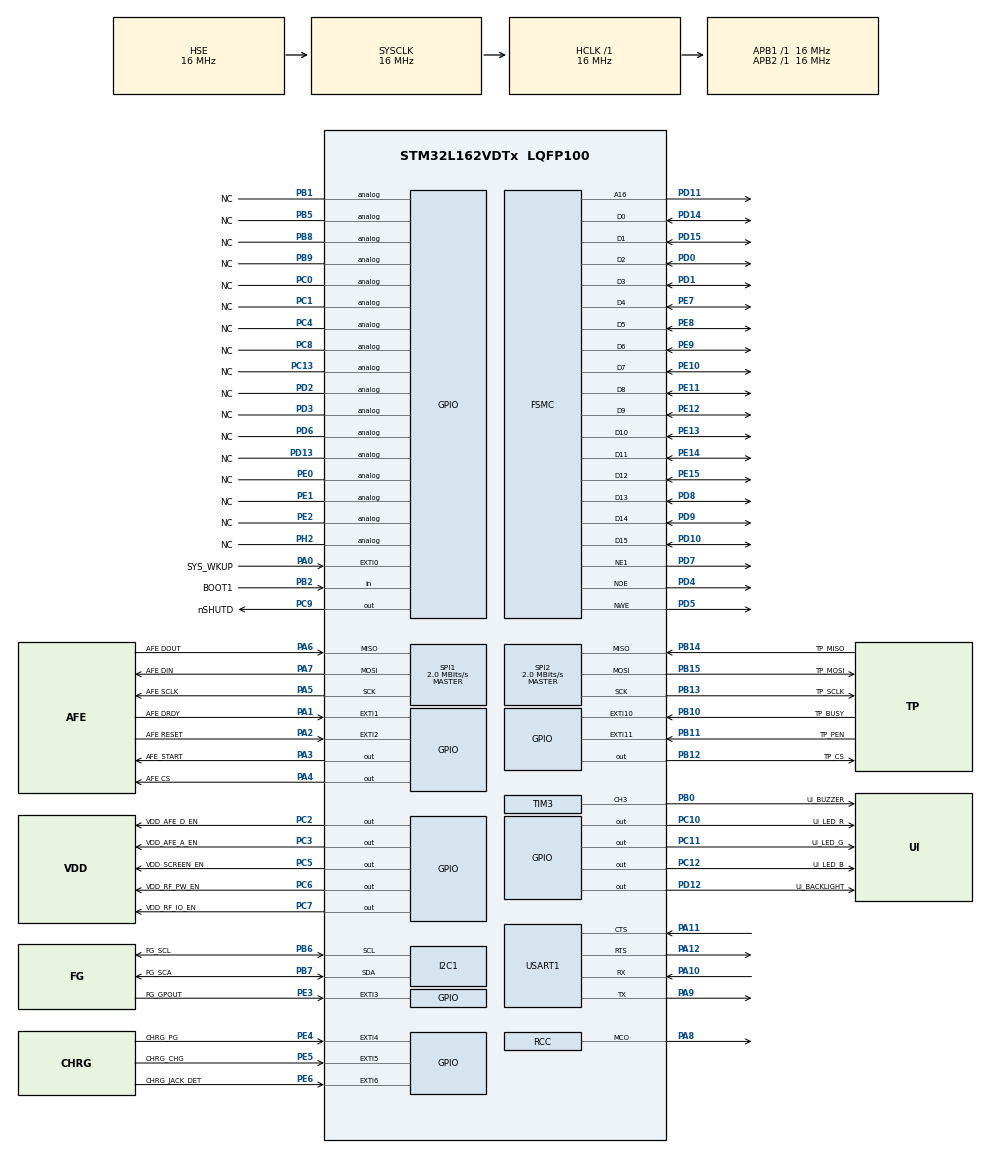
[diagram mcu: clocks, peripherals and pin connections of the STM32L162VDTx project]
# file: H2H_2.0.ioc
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Mcu.Family=STM32L1
Mcu.Name=STM32L162VDTx
Mcu.Package=LQFP100
NVIC.EXTI0_IRQn=true\:2\:0\:true\:false\:true
NVIC.EXTI15_10_IRQn=true\:6\:0\:true\:false\:true
NVIC.EXTI1_IRQn=true\:3\:0\:true\:false\:true
NVIC.EXTI3_IRQn=true\:4\:0\:true\:false\:true
NVIC.PriorityGroup=NVIC_PRIORITYGROUP_4
NVIC.TIM6_IRQn=true\:1\:0\:true\:false\:true
PA0-WKUP1.GPIO_Label=SYS_WKUP
PA0-WKUP1.Signal=GPXTI0
PA1.GPIO_Label=AFE DRDY
PA1.Signal=GPXTI1
PA10.Mode=Asynchronous
PA10.Signal=USART1_RX
PA11.Mode=CTS_RTS
PA11.Signal=USART1_CTS
PA12.Mode=CTS_RTS
PA12.Signal=USART1_RTS
PA13.Mode=JTAG(5-pin)
PA13.Signal=SYS_JTMS-SWDIO
PA14.Mode=JTAG(5-pin)
PA14.Signal=SYS_JTCK-SWCLK
PA15.Mode=JTAG(5-pin)
PA15.Signal=SYS_JTDI
PA2.GPIO_Label=AFE RESET
PA2.Signal=GPXTI2
PA3.GPIO_Label=AFE_START
PA3.Signal=GPIO_Output
PA4.GPIO_Label=AFE CS
PA4.Signal=GPIO_Output
PA5.GPIO_Label=AFE SCLK
PA5.Mode=Full_Duplex_Master
PA5.Signal=SPI1_SCK
PA6.GPIO_Label=AFE DOUT
PA6.Mode=Full_Duplex_Master
PA6.Signal=SPI1_MISO
PA7.GPIO_Label=AFE DIN
PA7.Mode=Full_Duplex_Master
PA7.Signal=SPI1_MOSI
PA8.Mode=Clock-out
PA8.Signal=RCC_MCO
PA9.Mode=Asynchronous
PA9.Signal=USART1_TX
PB0.GPIO_Label=UI_BUZZER
PB0.Signal=S_TIM3_CH3
PB1.GPIO_Label=NC
PB1.Signal=GPIO_Analog
PB10.GPIO_Label=TP_BUSY
PB10.Signal=GPXTI10
PB11.GPIO_Label=TP_PEN
PB11.GPIO_ModeDefaultEXTI=GPIO_MODE_IT_FALLING
PB11.Signal=GPXTI11
PB12.GPIO_Label=TP_CS
PB12.Signal=GPIO_Output
PB13.GPIO_Label=TP_SCLK
PB13.Mode=Full_Duplex_Master
PB13.Signal=SPI2_SCK
PB14.GPIO_Label=TP_MISO
PB14.Mode=Full_Duplex_Master
PB14.Signal=SPI2_MISO
PB15.GPIO_Label=TP_MOSI
PB15.Mode=Full_Duplex_Master
PB15.Signal=SPI2_MOSI
PB2.GPIO_Label=BOOT1
PB2.Signal=GPIO_Input
PB3.Mode=JTAG(5-pin)
PB3.Signal=SYS_JTDO-TRACESWO
PB4.Mode=JTAG(5-pin)
PB4.Signal=SYS_JTRST
PB5.GPIO_Label=NC
PB5.Signal=GPIO_Analog
PB6.GPIO_Label=FG_SCL
PB6.Mode=I2C
PB6.Signal=I2C1_SCL
PB7.GPIO_Label=FG_SCA
PB7.Mode=I2C
PB7.Signal=I2C1_SDA
PB8.GPIO_Label=NC
PB8.Signal=GPIO_Analog
PB9.GPIO_Label=NC
PB9.Signal=GPIO_Analog
PC0.GPIO_Label=NC
PC0.Signal=GPIO_Analog
PC1.GPIO_Label=NC
PC1.Signal=GPIO_Analog
PC10.GPIO_Label=UI_LED_R
PC10.GPIO_PuPd=GPIO_PULLDOWN
PC10.Signal=GPIO_Output
PC11.GPIO_Label=UI_LED_G
PC11.GPIO_PuPd=GPIO_PULLDOWN
PC11.Signal=GPIO_Output
PC12.GPIO_Label=UI_LED_B
PC12.GPIO_PuPd=GPIO_PULLDOWN
PC12.Signal=GPIO_Output
PC13-WKUP2.GPIO_Label=NC
PC13-WKUP2.Signal=GPIO_Analog
PC14-OSC32_IN.GPIO_Label=X2_P
PC14-OSC32_IN.Mode=LSE-External-Oscillator
PC14-OSC32_IN.Signal=RCC_OSC32_IN
PC15-OSC32_OUT.GPIO_Label=X2_N
PC15-OSC32_OUT.Mode=LSE-External-Oscillator
PC15-OSC32_OUT.Signal=RCC_OSC32_OUT
PC2.GPIO_Label=VDD_AFE_D_EN
PC2.PinState=GPIO_PIN_SET
PC2.Signal=GPIO_Output
PC3.GPIO_Label=VDD_AFE_A_EN
PC3.PinState=GPIO_PIN_SET
PC3.Signal=GPIO_Output
PC4.GPIO_Label=NC
PC4.Signal=GPIO_Analog
PC5.GPIO_Label=VDD_SCREEN_EN
PC5.PinState=GPIO_PIN_SET
PC5.Signal=GPIO_Output
PC6.GPIO_Label=VDD_RF_PW_EN
PC6.PinState=GPIO_PIN_SET
PC6.Signal=GPIO_Output
PC7.GPIO_Label=VDD_RF_IO_EN
PC7.PinState=GPIO_PIN_SET
PC7.Signal=GPIO_Output
PC8.GPIO_Label=NC
PC8.Signal=GPIO_Analog
PC9.GPIO_Label=nSHUTD
PC9.Signal=GPIO_Output
PD0.Mode=16b-d1
PD0.Signal=FSMC_D2
PD1.Mode=16b-d1
PD1.Signal=FSMC_D3
PD10.Mode=16b-d1
PD10.Signal=FSMC_D15
PD11.Mode=A16_1
PD11.Signal=FSMC_A16
PD12.GPIO_Label=UI_BACKLIGHT
PD12.PinState=GPIO_PIN_SET
PD12.Signal=GPIO_Output
PD13.GPIO_Label=NC
PD13.Signal=GPIO_Analog
PD14.Mode=16b-d1
PD14.Signal=FSMC_D0
PD15.Mode=16b-d1
PD15.Signal=FSMC_D1
PD2.GPIO_Label=NC
PD2.Signal=GPIO_Analog
PD3.GPIO_Label=NC
PD3.Signal=GPIO_Analog
PD4.Mode=Lcd1
PD4.Signal=FSMC_NOE
PD5.Mode=Lcd1
PD5.Signal=FSMC_NWE
PD6.GPIO_Label=NC
PD6.Signal=GPIO_Analog
PD7.Mode=NorPsramChipSelect1_1
PD7.Signal=FSMC_NE1
PD8.Mode=16b-d1
PD8.Signal=FSMC_D13
PD9.Mode=16b-d1
PD9.Signal=FSMC_D14
PE0.GPIO_Label=NC
PE0.Signal=GPIO_Analog
PE1.GPIO_Label=NC
PE1.Signal=GPIO_Analog
PE10.Mode=16b-d1
PE10.Signal=FSMC_D7
PE11.Mode=16b-d1
PE11.Signal=FSMC_D8
PE12.Mode=16b-d1
PE12.Signal=FSMC_D9
PE13.Mode=16b-d1
PE13.Signal=FSMC_D10
PE14.Mode=16b-d1
PE14.Signal=FSMC_D11
PE15.Mode=16b-d1
PE15.Signal=FSMC_D12
PE2.GPIO_Label=NC
PE2.Signal=GPIO_Analog
PE3.GPIO_Label=FG_GPOUT
PE3.GPIO_ModeDefaultEXTI=GPIO_MODE_IT_FALLING
PE3.Signal=GPXTI3
PE4.GPIO_Label=CHRG_PG
PE4.Signal=GPXTI4
PE5.GPIO_Label=CHRG_CHG
PE5.Signal=GPXTI5
PE6-WKUP3.GPIO_Label=CHRG_JACK_DET
PE6-WKUP3.Signal=GPXTI6
PE7.Mode=16b-d1
PE7.Signal=FSMC_D4
PE8.Mode=16b-d1
PE8.Signal=FSMC_D5
PE9.Mode=16b-d1
PE9.Signal=FSMC_D6
PH0-OSC_IN.GPIO_Label=X1_P
PH0-OSC_IN.Mode=HSE-External-Oscillator
PH0-OSC_IN.Signal=RCC_OSC_IN
PH1-OSC_OUT.GPIO_Label=X1_N
PH1-OSC_OUT.Mode=HSE-External-Oscillator
PH1-OSC_OUT.Signal=RCC_OSC_OUT
PH2.GPIO_Label=NC
PH2.Signal=GPIO_Analog
ProjectManager.HeapSize=0x400
ProjectManager.StackSize=0x200
ProjectManager.TargetToolchain=EWARM
RCC.AHBFreq_Value=16000000
RCC.APB1Freq_Value=16000000
RCC.APB1TimFreq_Value=16000000
RCC.APB2Freq_Value=16000000
RCC.APB2TimFreq_Value=16000000
RCC.EnbaleCSS=true
RCC.HCLKFreq_Value=16000000
RCC.HSE_VALUE=16000000
RCC.HSI_VALUE=16000000
RCC.MSI_VALUE=2097000
RCC.PLLSourceVirtual=RCC_PLLSOURCE_HSE
RCC.RCC_MCOSource=RCC_MCO1SOURCE_LSE
RCC.SYSCLKFreq_VALUE=16000000
RCC.SYSCLKSource=RCC_SYSCLKSOURCE_HSE
RCC.USBOutput=24000000
RCC.VCOOutputFreq_Value=48000000
SH.S_TIM3_CH3.0=TIM3_CH3,PWM Generation3 CH3
SPI1.BaudRatePrescaler=SPI_BAUDRATEPRESCALER_8
SPI1.CalculateBaudRate=2.0 MBits/s
SPI1.Mode=SPI_MODE_MASTER
SPI2.BaudRatePrescaler=SPI_BAUDRATEPRESCALER_8
SPI2.CalculateBaudRate=2.0 MBits/s
SPI2.Mode=SPI_MODE_MASTER
TIM3.Channel-PWM\ Generation3\ CH3=TIM_CHANNEL_3
TIM3.Period=5000
TIM3.Prescaler=9
TIM3.Pulse-PWM\ Generation3\ CH3=1000
TIM6.Period=1000
TIM6.Prescaler=16000
TIM6.TIM_MasterOutputTrigger=TIM_TRGO_UPDATE
VP_TIM3_VS_ClockSourceINT.Mode=Internal
VP_TIM6_VS_ClockSourceINT.Mode=Enable_Timer
board=H2H_2.0

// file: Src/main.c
/**
  ******************************************************************************
  * File Name          : main.c
  * Description        : Main program body
  ******************************************************************************
  *
  * COPYRIGHT(c) 2016 STMicroelectronics
  *
  * Redistribution and use in source and binary forms, with or without modification,
  * are permitted provided that the following conditions are met:
  *   1. Redistributions of source code must retain the above copyright notice,
  *      this list of conditions and the following disclaimer.
  *   2. Redistributions in binary form must reproduce the above copyright notice,
  *      this list of conditions and the following disclaimer in the documentation
  *      and/or other materials provided with the distribution.
  *   3. Neither the name of STMicroelectronics nor the names of its contributors
  *      may be used to endorse or promote products derived from this software
  *      without specific prior written permission.
  *
  * THIS SOFTWARE IS PROVIDED BY THE COPYRIGHT HOLDERS AND CONTRIBUTORS "AS IS"
  * AND ANY EXPRESS OR IMPLIED WARRANTIES, INCLUDING, BUT NOT LIMITED TO, THE
  * IMPLIED WARRANTIES OF MERCHANTABILITY AND FITNESS FOR A PARTICULAR PURPOSE ARE
  * DISCLAIMED. IN NO EVENT SHALL THE COPYRIGHT HOLDER OR CONTRIBUTORS BE LIABLE
  * FOR ANY DIRECT, INDIRECT, INCIDENTAL, SPECIAL, EXEMPLARY, OR CONSEQUENTIAL
  * DAMAGES (INCLUDING, BUT NOT LIMITED TO, PROCUREMENT OF SUBSTITUTE GOODS OR
  * SERVICES; LOSS OF USE, DATA, OR PROFITS; OR BUSINESS INTERRUPTION) HOWEVER
  * CAUSED AND ON ANY THEORY OF LIABILITY, WHETHER IN CONTRACT, STRICT LIABILITY,
  * OR TORT (INCLUDING NEGLIGENCE OR OTHERWISE) ARISING IN ANY WAY OUT OF THE USE
  * OF THIS SOFTWARE, EVEN IF ADVISED OF THE POSSIBILITY OF SUCH DAMAGE.
  *
  ******************************************************************************
  */
#include "stm32l1xx_hal.h"
#include "i2c.h"
#include "spi.h"
#include "tim.h"
#include "usart.h"
#include "gpio.h"
#include "fsmc.h"

/* USER CODE BEGIN Includes */
#include "afe.h"
#include "gauge.h"
#include "lcd.h"
#include "touch.h"

/* USER CODE END Includes */

/* USER CODE BEGIN PV */
/* Private variables ---------------------------------------------------------*/
#define QUARTER 350
/* USER CODE END PV */

void SystemClock_Config(void);

/* USER CODE BEGIN PFP */
/* Private function prototypes -----------------------------------------------*/
void two_secs_wakeup(void);
void note_flash(uint16_t dur , uint16_t frec);
void epic_sax_guy(void);
/* USER CODE END PFP */

/* USER CODE BEGIN 0 */
extern SRAM_HandleTypeDef hsram1;
extern color_t background_color;

uint16_t fg_soc;
touch_pos_t last_pos;
char bat_soc[4];

char x_pos[5];
char y_pos[5];
char pressure[5];

#define LCD_REG        ((uint32_t *)(FSMC_BASE))
#define LCD_DATA       ((uint32_t *)(FSMC_BASE + 0x00020000U))  //See p.620 of STM32L162VD ref. manual
/* USER CODE END 0 */

int main(void)
{

  /* MCU Configuration----------------------------------------------------------*/

  /* Reset of all peripherals, Initializes the Flash interface and the Systick. */
  HAL_Init();

  /* Configure the system clock */
  SystemClock_Config();

  /* Initialize all configured peripherals */
  MX_GPIO_Init();
  MX_FSMC_Init();
  MX_I2C1_Init();
  MX_SPI1_Init();
  MX_SPI2_Init();
  MX_TIM3_Init();
  MX_USART1_UART_Init();
  MX_TIM6_Init();

  /* USER CODE BEGIN 2 */
  afe_init();

    uint8_t level = 80;
    color_t dot_color;
    color_t text_color;
    uint8_t cntl_byte = 0;

    uint16_t voltage, temperature, int_temp;
    int16_t avg_current, max_current;

    afe_init();
    lcd_init();
    lcd_set_brightness(level);
    fg_init();
    touch_init();

    background_color = (color_t) COLOR_BLACK;
    dot_color = (color_t) COLOR_WHITE;
    text_color = (color_t) COLOR_GREEN;

    char string[] = "60";

    fg_soc = fg_read_reg16(FG_SOC);
    /* Convert to string
     * http://www.keil.com/support/man/docs/c51/c51_sprintf.htm
     */
    sprintf(bat_soc, "%d", fg_soc);

    /* Draw it */
    lcd_draw_string(bat_soc, myriad_pro_semibold28x39_num, &dot_color, 470, 100);

  /* USER CODE END 2 */

  /* Infinite loop */
  /* USER CODE BEGIN WHILE */
    while(1)
    {
      /* Fuel gauge data */
//      temperature = fg_read_reg16(FG_TEMP);
//      voltage = fg_read_reg16(FG_VOLT);
//      avg_current = fg_read_reg16(FG_AVG_CURRENT);
//      int_temp = fg_read_reg16(FG_INTERNAL_TEMP);
//      max_current = fg_read_reg16(FG_MAX_LOAD_CURRENT);

      /* Draw text */
//      lcd_draw_string("Ya no te pasas por el parque a", myriad_pro_semibold17x23, &text_color, 230, 240);
//      lcd_draw_string(string, myriad_pro_semibold28x39_num, &dot_color, 470, 230);
//      lcd_draw_string("bpm", myriad_pro_semibold17x23, &text_color, 510, 240);

      touch_get_position(&last_pos);

      sprintf(x_pos, "%d", last_pos.x_pos);
      sprintf(y_pos, "%d", last_pos.y_pos);
      sprintf(pressure, "%d", last_pos.pressure);

      lcd_draw_string(x_pos, myriad_pro_semibold17x23, &text_color, 100, 160);
      lcd_draw_string(y_pos, myriad_pro_semibold17x23, &text_color, 250, 160);
      lcd_draw_string(pressure, myriad_pro_semibold17x23, &text_color, 400, 160);

      /* Wait and erase text */
      //HAL_GPIO_TogglePin(GPIOC, UI_LED_R_Pin|UI_LED_G_Pin|UI_LED_B_Pin);
//      HAL_Delay(500);
//      lcd_delete_string(string, myriad_pro_semibold28x39_num, 470, 230);

      lcd_delete_string(x_pos, myriad_pro_semibold17x23, 100, 160);
      lcd_delete_string(y_pos, myriad_pro_semibold17x23, 250, 160);
      lcd_delete_string(pressure, myriad_pro_semibold17x23, 400, 160);

      /* Count */
//      if(string[1] < '9')
//      {
//        string[1] = string[1] + 1;
//      }
//      else
//      {
//        string[1] = '0';
//      }
    }
  /* USER CODE END WHILE */

  }

}

/** System Clock Configuration
*/
void SystemClock_Config(void)
{

  RCC_OscInitTypeDef RCC_OscInitStruct;
  RCC_ClkInitTypeDef RCC_ClkInitStruct;

  __HAL_RCC_PWR_CLK_ENABLE();

  __HAL_PWR_VOLTAGESCALING_CONFIG(PWR_REGULATOR_VOLTAGE_SCALE1);

  RCC_OscInitStruct.OscillatorType = RCC_OSCILLATORTYPE_HSE|RCC_OSCILLATORTYPE_LSE;
  RCC_OscInitStruct.HSEState = RCC_HSE_ON;
  RCC_OscInitStruct.LSEState = RCC_LSE_ON;
  RCC_OscInitStruct.PLL.PLLState = RCC_PLL_NONE;
  HAL_RCC_OscConfig(&RCC_OscInitStruct);

  RCC_ClkInitStruct.ClockType = RCC_CLOCKTYPE_HCLK|RCC_CLOCKTYPE_SYSCLK
                              |RCC_CLOCKTYPE_PCLK1|RCC_CLOCKTYPE_PCLK2;
  RCC_ClkInitStruct.SYSCLKSource = RCC_SYSCLKSOURCE_HSE;
  RCC_ClkInitStruct.AHBCLKDivider = RCC_SYSCLK_DIV1;
  RCC_ClkInitStruct.APB1CLKDivider = RCC_HCLK_DIV1;
  RCC_ClkInitStruct.APB2CLKDivider = RCC_HCLK_DIV1;
  HAL_RCC_ClockConfig(&RCC_ClkInitStruct, FLASH_LATENCY_0);

  HAL_RCC_MCOConfig(RCC_MCO1, RCC_MCO1SOURCE_LSE, RCC_MCODIV_1);

  HAL_RCC_EnableCSS();

  HAL_SYSTICK_Config(HAL_RCC_GetHCLKFreq()/1000);

  HAL_SYSTICK_CLKSourceConfig(SYSTICK_CLKSOURCE_HCLK);

  /* SysTick_IRQn interrupt configuration */
  HAL_NVIC_SetPriority(SysTick_IRQn, 0, 0);
}

/* USER CODE BEGIN 4 */
/**
  * @brief  Implements the initial delay of 2secs for wake up .
  * @param  None
  * @retval None
*/
void two_secs_wakeup(void){
  // Checks if the system is resumed from standby
  if (__HAL_PWR_GET_FLAG(PWR_FLAG_WU) != RESET)
  {
    __HAL_PWR_CLEAR_FLAG(PWR_FLAG_WU);
    wk_falling_edge_detection();
    HAL_Delay(2000);
    if (__HAL_GPIO_EXTI_GET_IT(GPIO_PIN_0) != RESET)
    {
      __HAL_GPIO_EXTI_CLEAR_IT(GPIO_PIN_0);
      HAL_PWR_EnableWakeUpPin(PWR_WAKEUP_PIN1);
      HAL_PWR_EnterSTANDBYMode();
    }
  }

}
/**
  * @brief  Activate PWM for note and 3 leds for white flashing.
  * @param  dur:duration of the note in ms.
  * @param  frec:frequency of the note in Hz.
  * @retval None
*/

void note_flash(uint16_t dur , uint16_t frec){
  uint16_t period = 16000000/((htim3.Init.Prescaler + 1)*frec);
  htim3.Init.Period = period;
  HAL_TIM_PWM_Init(&htim3);
  HAL_GPIO_WritePin(GPIOC, nSHUTD_Pin|UI_LED_R_Pin|UI_LED_G_Pin|UI_LED_B_Pin, GPIO_PIN_SET);
  HAL_TIM_PWM_Start(&htim3, TIM_CHANNEL_3);
  HAL_Delay(dur);
  HAL_GPIO_WritePin(GPIOC, nSHUTD_Pin|UI_LED_R_Pin|UI_LED_G_Pin|UI_LED_B_Pin, GPIO_PIN_RESET);
  HAL_TIM_PWM_Stop(&htim3, TIM_CHANNEL_3);
}

/**
  * @brief  Epic sax guy song.
  * @param  None
  * @retval None
*/
void epic_sax_guy(void){

  int i = 0;
  for( i = 0; i < 2; i++){
    note_flash(QUARTER>>1, 784);
    HAL_Delay((QUARTER*3)>>1);
    note_flash(QUARTER>>1, 784);
    HAL_Delay(50);
    note_flash(QUARTER>>2, 784);
    HAL_Delay(50);
    note_flash(QUARTER>>2, 784);
    HAL_Delay(50);
    note_flash(QUARTER>>2, 698);
    HAL_Delay(50);
    note_flash((QUARTER*3)>>2, 784);
    HAL_Delay(50);
  }
  note_flash(QUARTER>>1, 784);
  HAL_Delay(QUARTER);
  note_flash(QUARTER, 932);
  HAL_Delay(50);
  note_flash(QUARTER, 784);
  HAL_Delay(50);
  note_flash(QUARTER, 698);
  HAL_Delay(50);
  note_flash(QUARTER, 622);
  HAL_Delay(50);
  note_flash(QUARTER>>1, 523);
  HAL_Delay(50);
  note_flash(QUARTER>>1, 523);
  HAL_Delay(50);
  note_flash(QUARTER>>1, 587);
  HAL_Delay(50);
  note_flash(QUARTER>>1, 622);
  HAL_Delay(50);
  note_flash(QUARTER>>1, 523);
  HAL_Delay(50);
  note_flash(QUARTER, 784);
}

/* USER CODE END 4 */

/************************ (C) COPYRIGHT STMicroelectronics *****END OF FILE****/
